# myChip register map
Vendor: ARM Ltd.; Series: ARMCM3; File version: 1.2
CPU: CM3 r2p1, little endian, no MPU, no FPU, 3 interrupt priority bits
Registers are 32-bit, read-write, reset 0x0 unless marked. A register's access mark holds for its fields unless they carry their own. Offsets are from the block's base; [hi:lo] are bit positions; {n}, {i} and the like mark numbered series; 'fields as' and 'values as' point back to an identical list.

## CAN0
Base 0x40014000
Same registers: CAN1 0x40015000
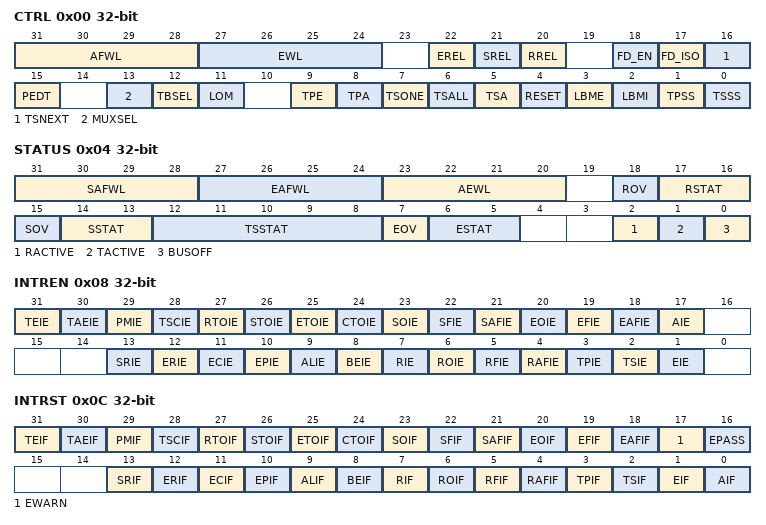
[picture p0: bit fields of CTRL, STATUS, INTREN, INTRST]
0x00 CTRL — CAN Control Register
  [31:28] AFWL — PRB接收缓冲区几乎满限制（PRB Almost Full Warning Limit）
  [27:24] EWL — 错误警告极限（Error Warning Limit）
  [22] EREL — ETB接收缓冲区释放（Receive Buffer Release）
  [21] SREL — SRB接收缓冲区释放（Receive Buffer Release）
  [20] RREL — PRB接收缓冲区释放（Receive Buffer Release）
  [18] FD_EN — CAN FD使能（CAN FD Enable）
  [17] FD_ISO — CAN FD ISO使能（CAN FD ISO Enable）
  [16] TSNEXT — STB发送缓冲区下一个使能（Transmit Buffer Secondary Next）
  [15] PEDT — CAN FD协议异常检测禁止（Protocol Exception Detect）
  [13] MUXSEL — CAN输入信号通路选择（Receive Multiplexer Select）
  [12] TBSEL — 发送缓冲器选择（Transmit Buffer Select）
  [11] LOM — 仅收听模式（Listen Only Mode）
  [9] TPE — PTB传输启用（PTB Transceiver Enable）
  [8] TPA — PTB传送中止（PTB Transmit Abort）
  [7] TSONE — STB传输下一帧（STB Transmit One Frame）
  [6] TSALL — STB传输所有帧（STB Transmit All Frames）
  [5] TSA — STB传输中止（Transmit STB Abort）
  [4] RESET — CAN复位控制位（RESET request bit）
  [3] LBME — 外部的环回模式（External Loop Back）
  [2] LBMI — 内部的环回模式（Internal Loop Back）
  [1] TPSS — PTB的单发传输模式（Transmission Primary Single Shot mode for PTB）
  [0] TSSS — STB的单发传输模式（Transmission Secondary Single Shot mode for STB）
0x04 STATUS — CAN Status Register
  [31:28] SAFWL — SRB接收缓冲区几乎满限制（SRB Almost Full Warning Limit）
  [27:24] EAFWL — ETB接收缓冲区几乎满限制（ETB Almost Full Warning Limit）
  [23:20] AEWL — STB发送缓冲区几乎空限制（STB Almost Empty Warning Limit）
  [18] ROV ro — PRB接收缓冲区溢出（PRB Receive Buffer Overflow）
  [17:16] RSTAT ro — PRB接收缓冲区状态（PRB Receive Buffer Status）
  [15] SOV ro — SRB接收缓冲区溢出（SRB Receive Buffer Overflow）
  [14:13] SSTAT ro — SRB接收缓冲区状态（SRB Receive Buffer Status）
  [12:8] TSSTAT ro — STB传输buffer状态位（Transmission Secondary Status bits）
  [7] EOV ro — ETB接收缓冲区溢出（ETB Receive Buffer Overflow）
  [6:5] ESTAT ro — ETB接收缓冲区状态（ETB Receive Buffer Status）
  [2] RACTIVE ro — 接收状态位（Receive Status bit）
  [1] TACTIVE ro — 发送状态位（Transmit Status bit）
  [0] BUSOFF ro — 总线启动状态位（Bus Status bit）
0x08 INTREN — CAN Interrupt Enable Register
  [31] TEIE — STB已空中断使能位（STB Empty Interrupt Enable）
  [30] TAEIE — STB将空中断使能位（STB Almost Empty Interrupt Enable）
  [29] PMIE — 优先级消息中断使能位（Priority Message Interrupt Enable）
  [28] TSCIE — 时间戳计数中断使能位（Timestamp Interrupt Enable）
  [27] RTOIE — PRB接收超时中断使能位（PRB Timeout Interrupt Enable）
  [26] STOIE — SRB接收超时中断使能位（SRB Timeout Interrupt Enable）
  [25] ETOIE — ETB接收超时中断使能位（ETB Timeout Interrupt Enable）
  [24] CTOIE — 连续计数超时中断使能位（Cont Timeout Interrupt Enable）
  [23] SOIE — SRB溢出中断使能位（SRB Overrun Interrupt Enable）
  [22] SFIE — SRB已满中断使能位（SRB Full Interrupt Enable）
  [21] SAFIE — SRB将满中断使能位（SRB Almost Full Interrupt Enable）
  [20] EOIE — ETB溢出中断使能位（ETB Overrun Interrupt Enable）
  [19] EFIE — ETB已满中断使能位（ETB Full Interrupt Enable）
  [18] EAFIE — ETB将满中断使能位（ETB Almost Full Interrupt Enable）
  [17] AIE — 中止中断使能位（Abort Interrupt Enable）
  [13] SRIE — SRB接收中断使能位（SRB Receive Interrupt Enable）
  [12] ERIE — ETB接收中断使能位（ETB Receive Interrupt Enable）
  [11] ECIE — 错误计数中断使能位（Error Counter Interrupt Enable）
  [10] EPIE — 被动错误中断使能位（Error Passive Interrupt Enable）
  [9] ALIE — 仲裁丢失中断使能位（Arbitration Lost Interrupt Enable）
  [8] BEIE — 总线错误中断使能位（Bus Error Interrupt Enable）
  [7] RIE — PRB接收中断使能位（PRB Receive Interrupt Enable）
  [6] ROIE — PRB溢出中断使能位（PRB Overrun Interrupt Enable）
  [5] RFIE — PRB已满中断使能位（PRB Full Interrupt Enable）
  [4] RAFIE — PRB将满中断使能位（PRB Almost Full Interrupt Enable）
  [3] TPIE — PTB传输中断使能位（PTB Transmission Interrupt Enable）
  [2] TSIE — STB传输中断使能位（STB Transmission Interrupt Enable）
  [1] EIE — 出错中断使能位（Error Interrupt Enable）
0x0C INTRST — CAN Interrupt Status Register
  [31] TEIF ro — STB已空中断标志（STB Empty Interrupt Flag）
  [30] TAEIF ro — STB将空中断标志（STB Almost Empty Interrupt Flag）
  [29] PMIF — 优先级消息中断标志（Priority Message Interrupt Flag）
  [28] TSCIF — 时间戳计数中断标志（Timestamp Interrupt Flag）
  [27] RTOIF — PRB接收超时中断标志（PRB Timeout Interrupt Flag）
  [26] STOIF — SRB接收超时中断标志（SRB Timeout Interrupt Flag）
  [25] ETOIF — ETB接收超时中断标志（ETB Timeout Interrupt Flag）
  [24] CTOIF — 连续计数超时中断标志（Cont Timeout Interrupt Flag）
  [23] SOIF — SRB溢出中断标志（SRB Overflow Interrupt Flag）
  [22] SFIF — SRB满中断标志（SRB Full Interrupt Flag）
  [21] SAFIF — SRB几乎满中断标志（SRB Almost Full Interrupt Flag）
  [20] EOIF — ETB溢出中断标志（ETB Overflow Interrupt Flag）
  [19] EFIF — ETB满中断标志（ETB Full Interrupt Flag）
  [18] EAFIF — ETB几乎满中断标志（ETB Almost Full Interrupt Flag）
  [17] EWARN ro — 达到错误警告限制（Error Warning Limit Reached）
  [16] EPASS ro — 错误被动模式有效（Error Passive Mode Active）
  [13] SRIF — SRB接收中断标志（SRB Receive Interrupt Flag）
  [12] ERIF — ETB接收中断标志（ETB Receive Interrupt Flag）
  [11] ECIF — 错误计数中断标志（Error Counter Interrupt Flag）
  [10] EPIF — 错误被动中断标志（Error Passive Interrupt Flag）
  [9] ALIF — 仲裁丢失中断标志（Arbitration Lost Interrupt Flag）
  [8] BEIF — 总线错误中断标志（Bus Error Interrupt Flag）
  [7] RIF — PRB接收中断标志（PRB Receive Interrupt Flag）
  [6] ROIF — PRB溢出中断标志（PRB Overflow Interrupt Flag）
  [5] RFIF — PRB满中断标志（PRB Full Interrupt Flag）
  [4] RAFIF — PRB几乎满中断标志（PRB Almost Full Interrupt Flag）
  [3] TPIF — PTB传输中断标志（PTB Transmission Interrupt Flag）
  [2] TSIF — STB传输中断标志（STB Transmission Interrupt Flag）
  [1] EIF — 错误中断标志（Error Interrupt Flag）
  [0] AIF — 中止中断标志（Abort Interrupt Flag）
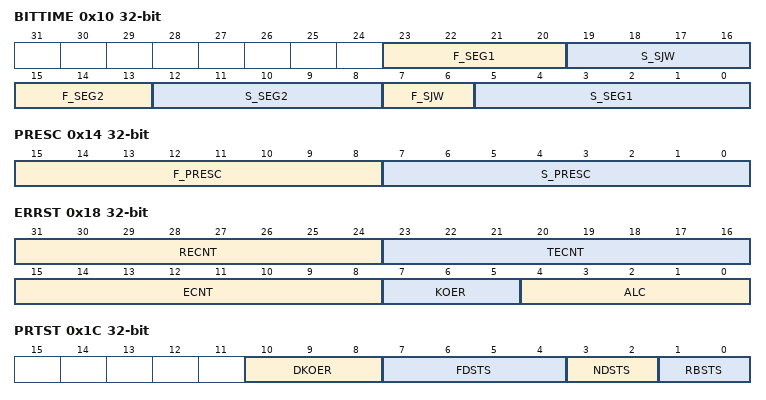
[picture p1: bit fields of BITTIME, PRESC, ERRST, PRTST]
0x10 BITTIME — CAN Bittime Setting Register
  [23:20] F_SEG1 — 快速模式下的位定时段1（Bit Timing Segment 1 (fast speed)）
  [19:16] S_SJW — 慢速模式下的同步跳转宽度（Synchronization Jump Width (slow speed)）
  [15:13] F_SEG2 — 快速模式下的位定时段2（Bit Timing Segment 2 (fast speed)）
  [12:8] S_SEG2 — 慢速模式小的为定时段2（Bit Timing Segment 2(slow speed)）
  [7:6] F_SJW — 快速模式下的同步跳转宽度（Synchronization Jump Width (fast speed)）
  [5:0] S_SEG1 — 慢速模式下的位定时段1（Bit Timing Segment 1 (slow speed)）
0x14 PRESC — CAN Prescaler Registers
  [15:8] F_PRESC — 快速模式下的预分频（Prescaler (fast speed)）
  [7:0] S_PRESC — 低速模式下的预分频（Prescaler (slow speed)）
0x18 ERRST — CAN Error Status Register
  [31:24] RECNT ro — 接收错误计数（number of errors during reception）
  [23:16] TECNT ro — 发送错误计数（number of errors during transmission）
  [15:8] ECNT ro — 错误计数（number of errors）
  [7:5] KOER ro — 错误类型标志位(Kind Of Error (Error code))
  [4:0] ALC ro — 仲裁丢失捕获（Arbitration Lost Capture）
0x1C PRTST — CAN Protocol Status Register
  [10:8] DKOER ro — 数据场错误类型标志位(Data Kind Of Error (Error code))
  [7:4] FDSTS ro — CAN接收的FD控制信息（CAN RX FD Status）
  [3:2] NDSTS ro — CAN节点状态（CAN Node Status）
  [1:0] RBSTS ro — CAN接收帧存储方式（CAN RX Buffer Status）
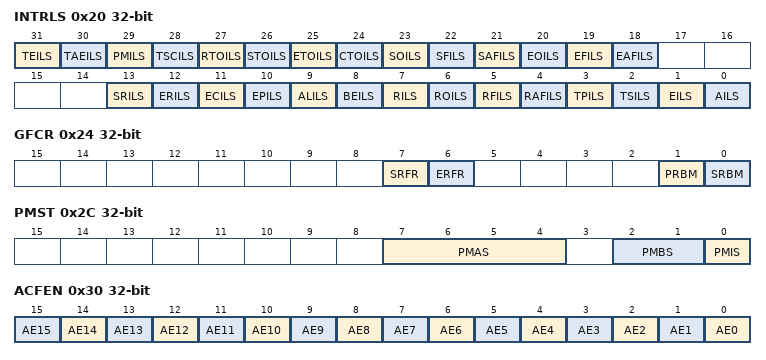
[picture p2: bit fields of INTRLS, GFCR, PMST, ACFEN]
0x20 INTRLS — CAN Interrupt Line Select Register
  [31] TEILS — STB已空中断线选择位（STB Empty Interrupt Line Select）
  [30] TAEILS — STB将空中断线选择位（STB Almost Empty Interrupt Line Select）
  [29] PMILS — 优先级消息中断线选择位（Priority Message Interrupt Line Select）
  [28] TSCILS — 时间戳计数中断线选择位（Timestamp Interrupt Line Select）
  [27] RTOILS — PRB接收超时中断线选择位（PRB Timeout Interrupt Line Select）
  [26] STOILS — SRB接收超时中断线选择位（SRB Timeout Interrupt Line Select）
  [25] ETOILS — ETB接收超时中断线选择位（ETB Timeout Interrupt Line Select）
  [24] CTOILS — 连续计数超时中断线选择位（Cont Timeout Interrupt Line Select）
  [23] SOILS — SRB溢出中断线选择位（SRB Overrun Interrupt Line Select）
  [22] SFILS — SRB已满中断线选择位（SRB Full Interrupt Line Select）
  [21] SAFILS — SRB将满中断线选择位（SRB Almost Full Interrupt Line Select）
  [20] EOILS — ETB溢出中断线选择位（ETB Overrun Interrupt Line Select）
  [19] EFILS — ETB已满中断线选择位（ETB Full Interrupt Line Select）
  [18] EAFILS — ETB将满中断线选择位（ETB Almost Full Interrupt Line Select）
  [13] SRILS — SRB接收中断线选择位（SRB Receive Interrupt Line Select）
  [12] ERILS — ETB接收中断线选择位（ETB Receive Interrupt Line Select）
  [11] ECILS — 错误计数中断线选择位（Error Counter Interrupt Line Select）
  [10] EPILS — 被动错误中断线选择位（Error Passive Interrupt Line Select）
  [9] ALILS — 仲裁丢失中断线选择位（Arbitration Lost Interrupt Line Select）
  [8] BEILS — 总线错误中断线选择位（Bus Error Interrupt Line Select）
  [7] RILS — PRB接收中断线选择位（PRB Receive Interrupt Line Select）
  [6] ROILS — PRB溢出中断线选择位（PRB Overrun Interrupt Line Select）
  [5] RFILS — PRB已满中断线选择位（PRB Full Interrupt Line Select）
  [4] RAFILS — PRB将满中断线选择位（PRB Almost Full Interrupt Line Select）
  [3] TPILS — PTB传输中断线选择位（PTB Transmission Interrupt Line Select）
  [2] TSILS — STB传输中断线选择位（STB Transmission Interrupt Line Select）
  [1] EILS — 出错中断线选择位（Error Interrupt Line Select）
  [0] AILS — 中止中断线选择位（Abort Interrupt Line Select）
0x24 GFCR — CAN Global Filter Control Register
  [7] SRFR — 常规远程帧屏蔽（Standard Remote Frames Reject）
  [6] ERFR — 拓展远程帧屏蔽（Extended Remote Frames Reject）
  [1] PRBM — PRB工作模式（PRB Working Mode）
  [0] SRBM — SRB工作模式（SRB Working Mode）
0x28 EMCR — CAN Extended Mask Control Register
  [28:0] EIDM — 拓展帧全局掩码（Extended ID Mask）
0x2C PMST — CAN Priority Message Status Register
  [7:4] PMAS ro — 高优先级消息验收状态（Priority Message Acceptance Status）
  [2:1] PMBS ro — 高优先级消息存储状态（Priority Message Buffer Status）
  [0] PMIS ro — 高优先级消息IDE状态（Priority Message IDE Status）
0x30 ACFEN — CAN ACF Enable
  [n] AE{n} (n=0..15) — 验收滤波器{n}启用（Acceptance filter {n} Enable）
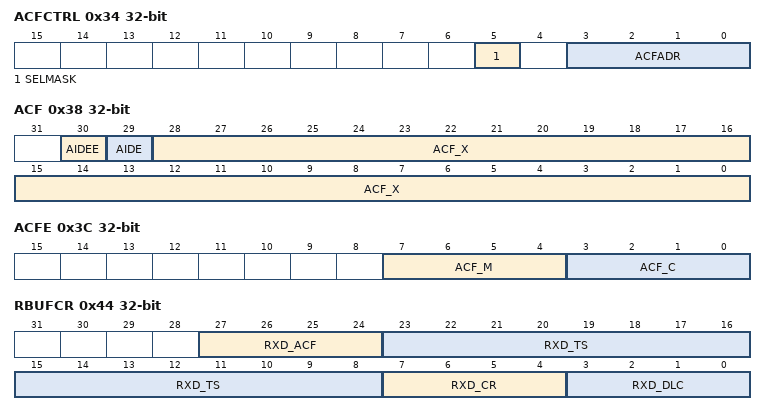
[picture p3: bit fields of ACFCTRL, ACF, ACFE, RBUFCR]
0x34 ACFCTRL — CAN ACF Control Register
  [5] SELMASK — 验收码和屏蔽码的选择位（Select acceptance MASK）
  [3:0] ACFADR — 验收滤波器的地址（acceptance filter address）
0x38 ACF — CAN ACF Data Register
  [30] AIDEE — 验收掩码IDE位的检查使能位（Acceptance mask IDE bit check enable）
  [29] AIDE — 验收掩码IDE位的控制位（Acceptance mask IDE bit value）
  [28:0] ACF_X — 当SELMASK=0：
0x3C ACFE — CAN ACF Data Extended Register
  [7:4] ACF_M — CAN验收滤波器的模式信息（CAN Acceptance Mode）
  [3:0] ACF_C — CAN验收滤波器的控制信息（CAN Acceptance Control）
0x40 RBUFID — CAN RX Buffer Read Register(ID)
  [31:0] RXD_ID ro — CAN接收的ID信息（CAN RX Identifier Data）
0x44 RBUFCR — CAN RX Buffer Read Register(Control)
  [27:24] RXD_ACF ro — CAN接收的验收滤波信息（CAN RX Acceptance Data）
  [23:8] RXD_TS ro — CAN接收的时间戳（CAN RX Data Timestamp）
  [7:4] RXD_CR ro — CAN接收的控制信息（CAN RX Control Data）
  [3:0] RXD_DLC ro — CAN接收的数据量（CAN RX DATA Count）
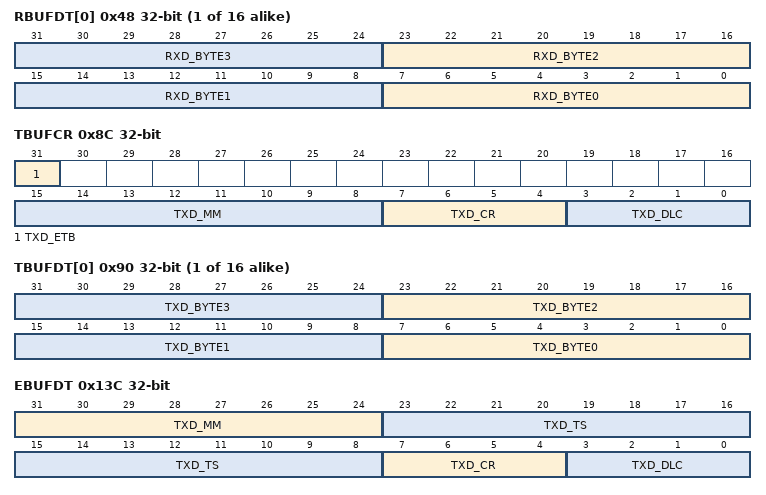
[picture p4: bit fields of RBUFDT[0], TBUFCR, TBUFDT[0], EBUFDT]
{0x48+4i} RBUFDT[{i}] (i=0..15) — CAN RX Buffer Read Register(Data)
  [8n+7:8n] RXD_BYTE{n} ro (n=0..3) — CAN接收的数据字节{n}（CAN RX Data Byte {n}）
0x88 TBUFID — CAN TX Buffer Write Register(ID)
  [31:0] TXD_ID — CAN发送的ID信息（CAN TX Identifier Data）
0x8C TBUFCR — CAN TX Buffer Write Register(Control)
  [31] TXD_ETB — CAN发送的信息是否写入ETB（CAN TX Event Buffer）
  [15:8] TXD_MM — CAN发送的帧标记（CAN TX Data Message Marker）
  [7:4] TXD_CR — CAN发送的控制信息（CAN TX Control Data）
  [3:0] TXD_DLC — CAN发送的数据量（CAN TX DATA Count）
{0x90+4i} TBUFDT[{i}] (i=0..15) — CAN TX Buffer Write Register(Data)
  [8n+7:8n] TXD_BYTE{n} (n=0..3) — CAN发送的数据字节{n}（CAN TX Data Byte {n}）
0x138 EBUFID — CAN ETB Buffer Read Register(ID)
  [31:0] TXD_ID ro — CAN发送的ID信息（CAN TX Identifier Data）
0x13C EBUFDT — CAN ETB Buffer Read Register(Data)
  [31:24] TXD_MM ro — CAN发送的帧标记（CAN TX Data Message Marker）
  [23:8] TXD_TS ro — CAN发送的时间戳（CAN TX Data Timestamp）
  [7:4] TXD_CR ro — CAN发送的控制信息（CAN TX Control Data）
  [3:0] TXD_DLC ro — CAN发送的数据量（CAN TX DATA Count）
0x140 SBUFID — CAN SRB Buffer Read Register(ID)
  [31:0] RXD_ID ro — CAN接收的ID信息（CAN RX Identifier Data）
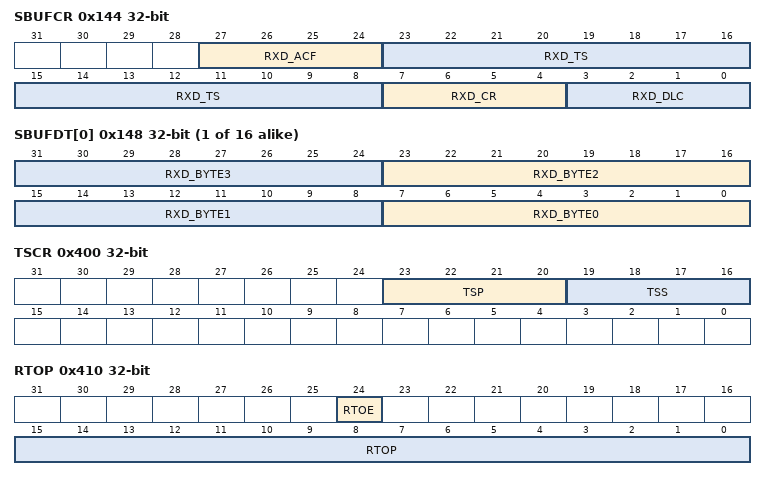
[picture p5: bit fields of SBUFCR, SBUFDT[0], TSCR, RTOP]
0x144 SBUFCR — CAN SRB Buffer Read Register(Control)
  fields as RBUFCR
{0x148+4i} SBUFDT[{i}] (i=0..15) — CAN SRB Buffer Read Register(Data)
  fields as RBUFDT[0]
0x400 TSCR — Timestamp Counter Control Register
  [23:20] TSP — 时间戳预分频（Timestamp Prescaler）
  [19:16] TSS — 时间戳选择（Timestamp Select）
0x404 TSC — Timestamp Counter Value Register
  [15:0] TSC ro — 时间戳计数（Timestamp Counter）
0x410 RTOP — PRB Timeout Counter Period Register
  [24] RTOE — PRB超时功能使能（PRB Timeout Enable）
  [15:0] RTOP — PRB超时功能周期（PRB Timeout Period）
0x414 RTOC — PRB Timeout Counter Value Register
  [15:0] RTOC ro — PRB超时功能计数（PRB Timeout Counter）
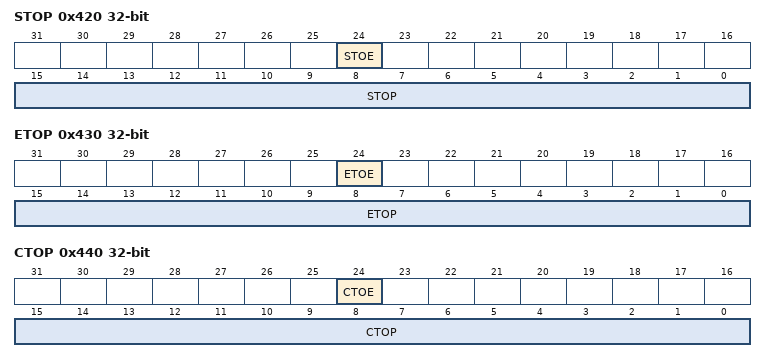
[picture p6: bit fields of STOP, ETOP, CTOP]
0x420 STOP — SRB Timeout Counter Period Register
  [24] STOE — SRB超时功能使能（SRB Timeout Enable）
  [15:0] STOP — SRB超时功能周期（SRB Timeout Period）
0x424 STOC — SRB Timeout Counter Value Register
  [15:0] STOC ro — SRB超时功能计数（SRB Timeout Counter）
0x430 ETOP — ETB Timeout Counter Period Register
  [24] ETOE — ETB超时功能使能（ETB Timeout Enable）
  [15:0] ETOP — ETB超时功能周期（ETB Timeout Period）
0x434 ETOC — ETB Timeout Counter Value Register
  [15:0] ETOC ro — ETB超时功能计数（ETB Timeout Counter）
0x440 CTOP — Continuous Timeout Counter Period Register
  [24] CTOE — 连续超时功能使能（Cont Timeout Enable）
  [15:0] CTOP — 连续超时功能周期（Cont Timeout Period）
0x444 CTOC — Continuous Timeout Counter Value Register
  [15:0] CTOC ro — 连续超时功能计数（Cont Timeout Counter）
